VERSION ""

NS_ :

BS_:

BU_: XXX

BO_ 85 EPB: 8 XXX
 SG_ EPB_ActiveFlag : 40|1@1+ (1,0) [0|1] "" XXX
 SG_ CheckSum : 56|8@1+ (1,0) [0|255] "" XXX

BO_ 140 NOTSURE: 8 XXX
 SG_ Heartbeat1 : 15|4@0+ (1,0) [0|15] "" XXX
 SG_ Heartbeat2 : 63|4@0+ (1,0) [0|15] "" XXX

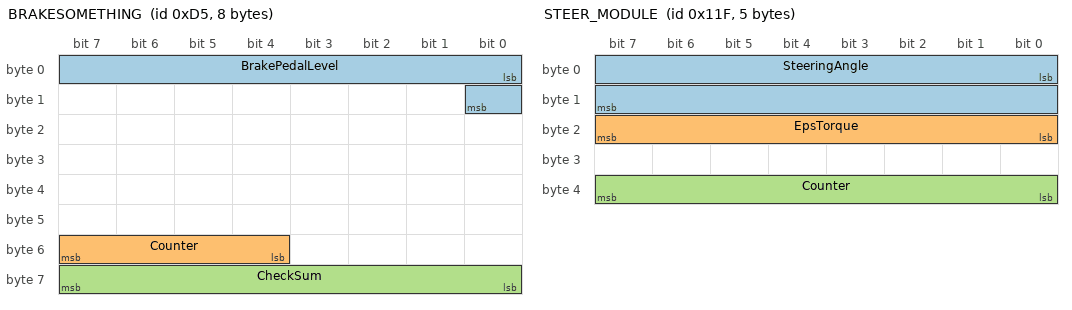
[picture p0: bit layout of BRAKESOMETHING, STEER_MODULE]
BO_ 213 BRAKESOMETHING: 8 XXX
 SG_ BrakePedalLevel : 0|9@1+ (1,0) [0|511] "" XXX
 SG_ Counter : 55|4@0+ (1,0) [0|15] "" XXX
 SG_ CheckSum : 56|8@1+ (1,0) [0|255] "" XXX

BO_ 269 BRAKESOMETHING2: 8 XXX
 SG_ BrakeLevelCoarse : 59|2@0+ (1,0) [0|3] "" XXX

BO_ 287 STEER_MODULE: 5 XXX
 SG_ SteeringAngle : 0|16@1- (0.1,0) [-450|450] "" XXX
 SG_ EpsTorque : 16|8@1+ (1,0) [0|1020] "" XXX
 SG_ Counter : 32|8@1+ (1,0) [0|255] "" XXX

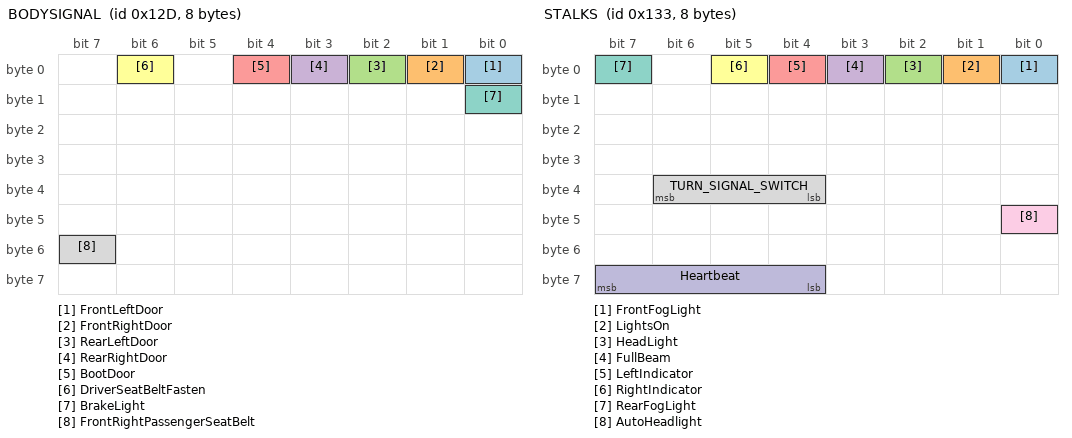
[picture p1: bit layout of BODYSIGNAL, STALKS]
BO_ 301 BODYSIGNAL: 8 XXX
 SG_ FrontLeftDoor : 0|1@0+ (1,0) [0|1] "" XXX
 SG_ FrontRightDoor : 1|1@0+ (1,0) [0|1] "" XXX
 SG_ RearLeftDoor : 2|1@0+ (1,0) [0|1] "" XXX
 SG_ RearRightDoor : 3|1@0+ (1,0) [0|1] "" XXX
 SG_ BootDoor : 4|1@0+ (1,0) [0|1] "" XXX
 SG_ DriverSeatBeltFasten : 6|1@0+ (1,0) [0|1] "" XXX
 SG_ BrakeLight : 8|1@0+ (1,0) [0|1] "" XXX
 SG_ FrontRightPassengerSeatBelt : 55|1@0+ (1,0) [0|1] "" XXX

BO_ 307 STALKS: 8 XXX
 SG_ FrontFogLight : 0|1@0+ (1,0) [0|1] "" XXX
 SG_ LightsOn : 1|1@1+ (1,0) [0|1] "" XXX
 SG_ HeadLight : 2|1@1+ (1,0) [0|1] "" XXX
 SG_ FullBeam : 3|1@1+ (1,0) [0|1] "" XXX
 SG_ LeftIndicator : 4|1@0+ (1,0) [0|1] "" XXX
 SG_ RightIndicator : 5|1@0+ (1,0) [0|1] "" XXX
 SG_ RearFogLight : 7|1@0+ (1,0) [0|1] "" XXX
 SG_ TURN_SIGNAL_SWITCH : 36|3@1+ (1,0) [0|7] "" XXX
 SG_ AutoHeadlight : 40|1@0+ (1,0) [0|1] "" XXX
 SG_ Heartbeat : 63|4@0+ (1,0) [0|15] "" XXX

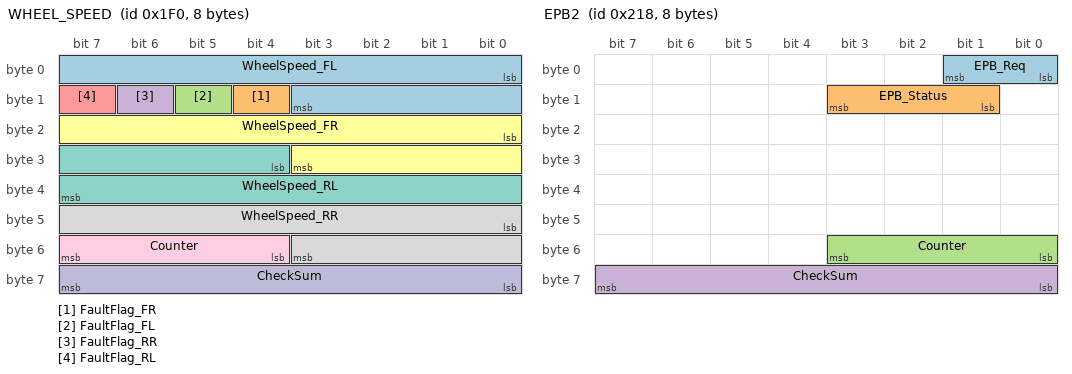
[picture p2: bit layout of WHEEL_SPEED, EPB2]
BO_ 496 WHEEL_SPEED: 8 XXX
 SG_ WheelSpeed_FL : 0|12@1+ (0.06875,0) [0|281.4625] "kph" XXX
 SG_ FaultFlag_FR : 12|1@1+ (1,0) [0|1] "" XXX
 SG_ FaultFlag_FL : 13|1@1+ (1,0) [0|1] "" XXX
 SG_ FaultFlag_RR : 14|1@1+ (1,0) [0|1] "" XXX
 SG_ FaultFlag_RL : 15|1@1+ (1,0) [0|1] "" XXX
 SG_ WheelSpeed_FR : 16|12@1+ (0.06875,0) [0|281.4625] "kph" XXX
 SG_ WheelSpeed_RL : 28|12@1+ (0.06875,0) [0|281.4625] "kph" XXX
 SG_ WheelSpeed_RR : 40|12@1+ (0.06875,0) [0|281.4625] "kph" XXX
 SG_ Counter : 52|4@1+ (1,0) [0|15] "" XXX
 SG_ CheckSum : 56|8@1+ (1,0) [0|255] "" XXX

BO_ 522 ENGINE_RPM: 8 XXX
 SG_ EngineRPM : 31|8@0+ (1,0) [0|255] "" XXX

BO_ 523 ENGINE_GAUGE: 8 XXX
 SG_ EngineRPM : 15|8@0+ (12,0) [0|0] "" XXX

BO_ 536 EPB2: 8 XXX
 SG_ EPB_Req : 0|2@1+ (1,0) [0|3] "" XXX
 SG_ EPB_Status : 9|3@1+ (1,0) [0|7] "" XXX
 SG_ Counter : 48|4@1+ (1,0) [0|15] "" XXX
 SG_ CheckSum : 56|8@1+ (1,0) [0|255] "" XXX

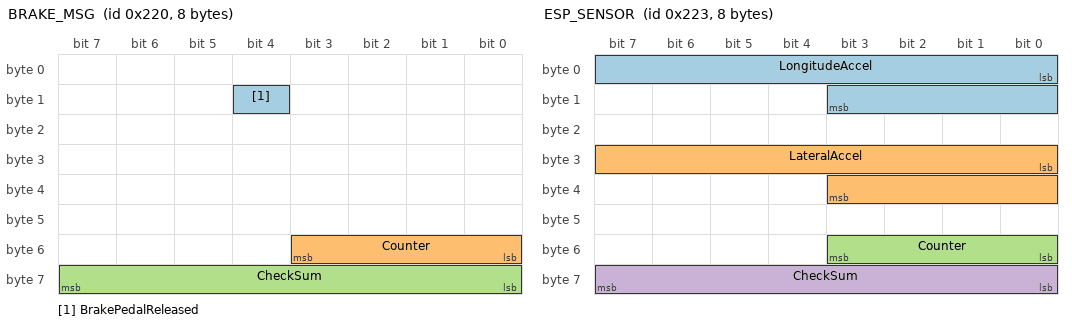
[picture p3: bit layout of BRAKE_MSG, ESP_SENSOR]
BO_ 544 BRAKE_MSG: 8 XXX
 SG_ BrakePedalReleased : 12|1@0+ (1,0) [0|1] "" XXX
 SG_ Counter : 51|4@0+ (1,0) [0|15] "" XXX
 SG_ CheckSum : 56|8@1+ (1,4) [0|255] "" XXX

BO_ 547 ESP_SENSOR: 8 XXX
 SG_ LongitudeAccel : 0|12@1- (0.02,-16) [-2848|1247] "" XXX
 SG_ LateralAccel : 24|12@1- (0.02,-16) [-2848|1247] "" XXX
 SG_ Counter : 51|4@0+ (1,0) [0|15] "" XXX
 SG_ CheckSum : 56|8@1+ (1,0) [0|255] "" XXX

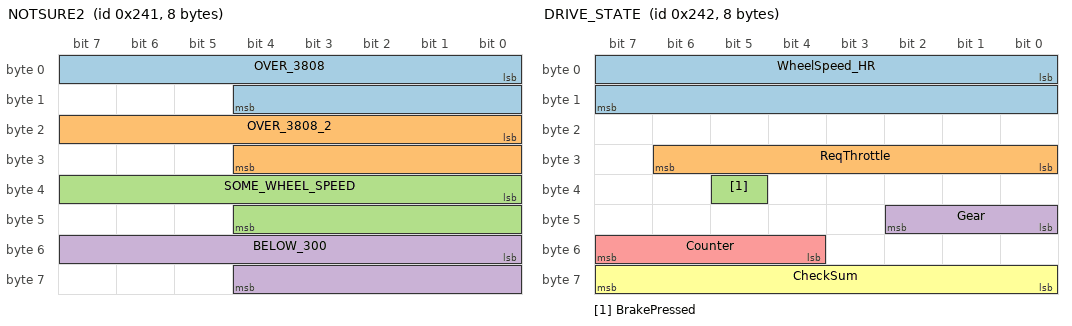
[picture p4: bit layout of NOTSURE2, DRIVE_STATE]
BO_ 577 NOTSURE2: 8 XXX
 SG_ OVER_3808 : 0|13@1+ (1,0) [0|255] "" XXX
 SG_ OVER_3808_2 : 16|13@1+ (1,0) [0|65535] "" XXX
 SG_ SOME_WHEEL_SPEED : 32|13@1- (0.06875,300) [0|15] "" XXX
 SG_ BELOW_300 : 48|13@1+ (0.05,0) [0|255] "" XXX

BO_ 578 DRIVE_STATE: 8 XXX
 SG_ WheelSpeed_HR : 0|16@1+ (0.01706666666,-512) [0|65535] "" XXX
 SG_ ReqThrottle : 30|7@0+ (1,0) [0|127] "" XXX
 SG_ BrakePressed : 37|1@0+ (1,0) [0|1] "" XXX
 SG_ Gear : 40|3@1+ (1,0) [0|7] "" XXX
 SG_ Counter : 55|4@0+ (1,0) [0|15] "" XXX
 SG_ CheckSum : 56|8@1+ (1,0) [0|255] "" XXX

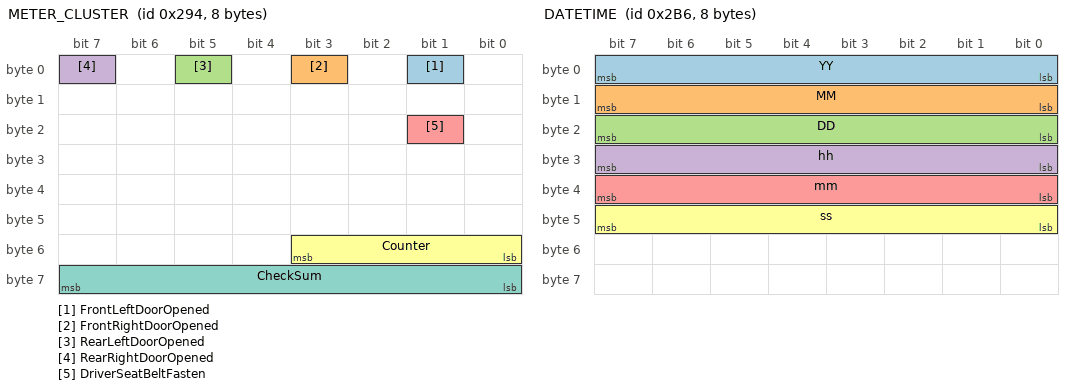
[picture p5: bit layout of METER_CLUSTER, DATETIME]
BO_ 660 METER_CLUSTER: 8 XXX
 SG_ FrontLeftDoorOpened : 1|1@1+ (1,0) [0|511] "" XXX
 SG_ FrontRightDoorOpened : 3|1@0+ (1,0) [0|1] "" XXX
 SG_ RearLeftDoorOpened : 5|1@1+ (1,0) [0|511] "" XXX
 SG_ RearRightDoorOpened : 7|1@0+ (1,0) [0|1] "" XXX
 SG_ DriverSeatBeltFasten : 17|1@0+ (1,0) [0|1] "" XXX
 SG_ Counter : 51|4@0+ (1,0) [0|15] "" XXX
 SG_ CheckSum : 56|8@1+ (1,0) [0|255] "" XXX

BO_ 694 DATETIME: 8 XXX
 SG_ YY : 7|8@0+ (1,0) [0|255] "" XXX
 SG_ MM : 15|8@0+ (1,0) [0|255] "" XXX
 SG_ DD : 23|8@0+ (1,0) [0|255] "" XXX
 SG_ hh : 31|8@0+ (1,0) [0|255] "" XXX
 SG_ mm : 39|8@0+ (1,0) [0|255] "" XXX
 SG_ ss : 47|8@0+ (1,0) [0|255] "" XXX

BO_ 790 MPC_LKAS_CTRL_AND_STATUS: 8 XXX
 SG_ AutoFullBeam_OnOff : 0|2@0+ (1,0) [0|1] "" XXX
 SG_ AutoFullBeamState : 1|1@0+ (1,0) [0|1] "" XXX
 SG_ LeftLaneState : 4|2@1+ (1,0) [0|3] "" XXX
 SG_ LKAS_Config : 6|2@1+ (1,0) [0|3] "" XXX
 SG_ SETME_0x1 : 8|2@1+ (1,0) [0|3] "" XXX
 SG_ ReqHandsOnSteeringWheel : 10|1@1+ (1,0) [0|1] "" XXX
 SG_ MPC_State : 11|4@1+ (1,0) [0|1] "" XXX
 SG_ LKAS_Output : 16|11@1- (1,0) [-1024|1023] "" XXX
 SG_ LKAS_Prepare : 27|1@1+ (1,0) [0|1] "" XXX
 SG_ LKAS_ACTIVE : 28|1@1+ (1,0) [0|3] "" XXX
 SG_ TrafficSignRecognition_OnOff : 30|1@0+ (1,0) [0|1] "" XXX
 SG_ SETME4_0x1 : 32|2@1+ (1,0) [0|3] "" XXX
 SG_ RightLaneState : 34|2@1+ (1,0) [0|3] "" XXX
 SG_ LKAS_OnOff : 36|1@1+ (1,0) [0|3] "" XXX
 SG_ SETME_0x0 : 38|2@1+ (1,0) [0|3] "" XXX
 SG_ TrafficSignRecognition_Result : 40|8@1+ (5,-5) [-5|1270] "" XXX
 SG_ LKAS_AlarmType : 49|2@0+ (1,0) [0|3] "" XXX
 SG_ SETME_0x3 : 51|2@0+ (1,0) [0|3] "" XXX
 SG_ Counter : 52|4@1+ (1,0) [0|15] "" XXX
 SG_ CheckSum : 56|8@1+ (1,0) [0|15] "" XXX

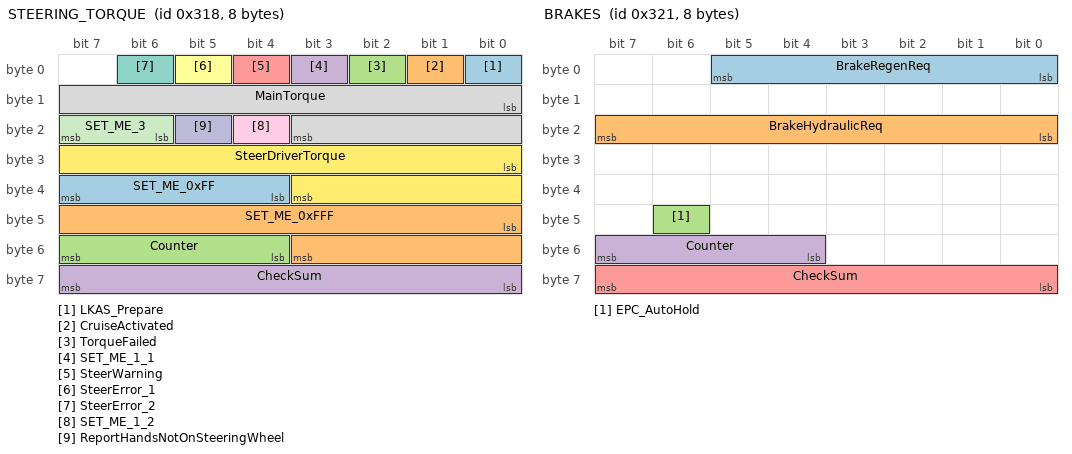
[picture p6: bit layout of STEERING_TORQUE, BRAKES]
BO_ 792 STEERING_TORQUE: 8 XXX
 SG_ LKAS_Prepare : 0|1@1+ (1,0) [0|1] "" XXX
 SG_ CruiseActivated : 1|1@1+ (1,0) [0|1] "" XXX
 SG_ TorqueFailed : 2|1@1+ (1,0) [0|1] "" XXX
 SG_ SET_ME_1_1 : 3|1@1+ (1,0) [0|1] "" XXX
 SG_ SteerWarning : 4|1@1+ (1,0) [0|1] "" XXX
 SG_ SteerError_1 : 5|1@1+ (1,0) [0|1] "" XXX
 SG_ SteerError_2 : 6|1@1+ (1,0) [0|1] "" XXX
 SG_ MainTorque : 8|12@1- (1,0) [-2048|2047] "" XXX
 SG_ SET_ME_1_2 : 20|1@1+ (1,0) [0|1] "" XXX
 SG_ ReportHandsNotOnSteeringWheel : 21|1@1+ (1,0) [0|1] "" XXX
 SG_ SET_ME_3 : 22|2@1+ (1,0) [0|15] "" XXX
 SG_ SteerDriverTorque : 24|12@1- (1,0) [-2048|2047] "" XXX
 SG_ SET_ME_0xFF : 36|4@1+ (1,0) [0|15] "" XXX
 SG_ SET_ME_0xFFF : 40|12@1+ (1,0) [0|4095] "" XXX
 SG_ Counter : 52|4@1+ (1,0) [0|15] "" XXX
 SG_ CheckSum : 56|8@1+ (1,0) [0|255] "" XXX

BO_ 801 BRAKES: 8 XXX
 SG_ BrakeRegenReq : 5|6@0+ (1,0) [0|63] "" XXX
 SG_ BrakeHydraulicReq : 23|8@0+ (1,0) [0|255] "" XXX
 SG_ EPC_AutoHold : 46|1@0+ (1,0) [0|1] "" XXX
 SG_ Counter : 55|4@0+ (1,0) [0|15] "" XXX
 SG_ CheckSum : 63|8@0+ (1,0) [0|255] "" XXX

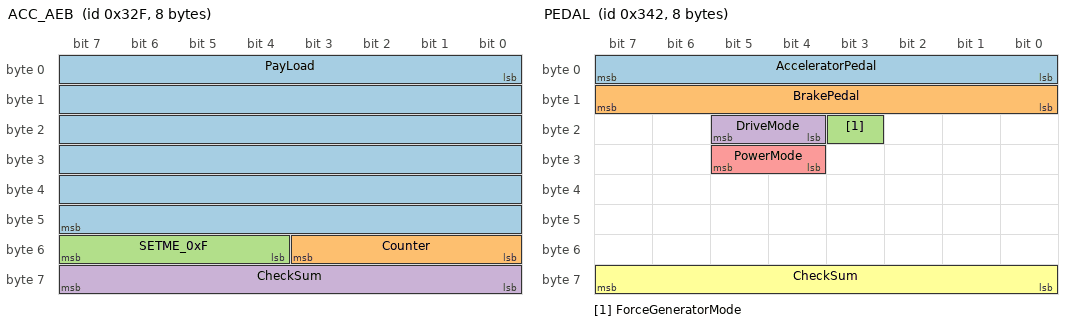
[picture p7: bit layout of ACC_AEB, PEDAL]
BO_ 815 ACC_AEB: 8 XXX
 SG_ PayLoad : 0|48@1+ (1,0) [0|4.5035996273705e+15] "" XXX
 SG_ Counter : 48|4@1+ (1,0) [0|15] "" XXX
 SG_ SETME_0xF : 55|4@0+ (1,0) [0|15] "" XXX
 SG_ CheckSum : 56|8@1+ (1,0) [0|255] "" XXX

BO_ 834 PEDAL: 8 XXX
 SG_ AcceleratorPedal : 0|8@1+ (0.01,0) [0|2.55] "" XXX
 SG_ BrakePedal : 8|8@1+ (0.01,0) [0|2.55] "" XXX
 SG_ ForceGeneratorMode : 19|1@1+ (1,0) [0|1] "" XXX
 SG_ DriveMode : 20|2@1+ (1,0) [0|255] "" XXX
 SG_ PowerMode : 28|2@1+ (1,0) [0|1] "" XXX
 SG_ CheckSum : 56|8@1+ (1,0) [0|255] "" XXX

BO_ 848 RADAR_NOTSURE: 8 XXX

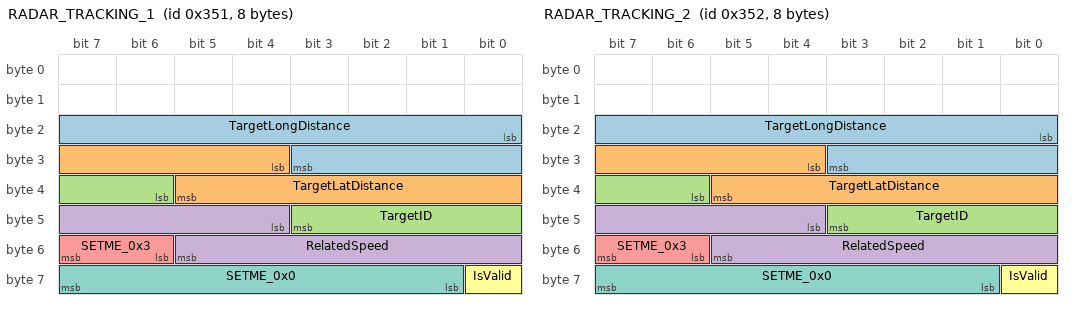
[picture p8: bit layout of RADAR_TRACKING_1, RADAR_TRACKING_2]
BO_ 849 RADAR_TRACKING_1: 8 XXX
 SG_ TargetLongDistance : 16|12@1- (0.0625,-4.5) [-61.44|61.41] "m" XXX
 SG_ TargetLatDistance : 28|10@1+ (0.0625,-32) [-15.36|15.33] "m" XXX
 SG_ TargetID : 38|6@1+ (1,0) [0|63] "" XXX
 SG_ RelatedSpeed : 44|10@1+ (1,-512) [-512|511] "km/s" XXX
 SG_ SETME_0x3 : 54|2@1+ (1,0) [0|3] "" XXX
 SG_ IsValid : 56|1@0+ (1,0) [0|1] "" XXX
 SG_ SETME_0x0 : 57|7@1+ (1,0) [0|127] "" XXX

BO_ 850 RADAR_TRACKING_2: 8 XXX
 SG_ TargetLongDistance : 16|12@1- (0.0625,-4.5) [-61.44|61.41] "m" XXX
 SG_ TargetLatDistance : 28|10@1+ (0.0625,-32) [-15.36|15.33] "m" XXX
 SG_ TargetID : 38|6@1+ (1,0) [0|63] "" XXX
 SG_ RelatedSpeed : 44|10@1+ (1,-512) [-512|511] "km/s" XXX
 SG_ SETME_0x3 : 54|2@1+ (1,0) [0|3] "" XXX
 SG_ IsValid : 56|1@0+ (1,0) [0|1] "" XXX
 SG_ SETME_0x0 : 57|7@1+ (1,0) [0|127] "" XXX

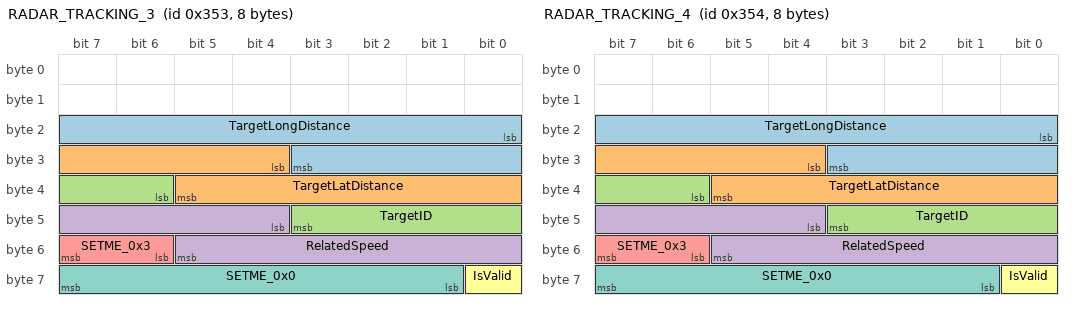
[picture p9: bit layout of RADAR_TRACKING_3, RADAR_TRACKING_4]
BO_ 851 RADAR_TRACKING_3: 8 XXX
 SG_ TargetLongDistance : 16|12@1- (0.0625,-4.5) [-61.44|61.41] "m" XXX
 SG_ TargetLatDistance : 28|10@1+ (0.0625,-32) [-15.36|15.33] "m" XXX
 SG_ TargetID : 38|6@1+ (1,0) [0|63] "" XXX
 SG_ RelatedSpeed : 44|10@1+ (1,-512) [-512|511] "km/s" XXX
 SG_ SETME_0x3 : 54|2@1+ (1,0) [0|3] "" XXX
 SG_ IsValid : 56|1@0+ (1,0) [0|1] "" XXX
 SG_ SETME_0x0 : 57|7@1+ (1,0) [0|127] "" XXX

BO_ 852 RADAR_TRACKING_4: 8 XXX
 SG_ TargetLongDistance : 16|12@1- (0.0625,-4.5) [-61.44|61.41] "m" XXX
 SG_ TargetLatDistance : 28|10@1+ (0.0625,-32) [-15.36|15.33] "m" XXX
 SG_ TargetID : 38|6@1+ (1,0) [0|63] "" XXX
 SG_ RelatedSpeed : 44|10@1+ (1,-512) [-512|511] "km/s" XXX
 SG_ SETME_0x3 : 54|2@1+ (1,0) [0|3] "" XXX
 SG_ IsValid : 56|1@0+ (1,0) [0|1] "" XXX
 SG_ SETME_0x0 : 57|7@1+ (1,0) [0|127] "" XXX

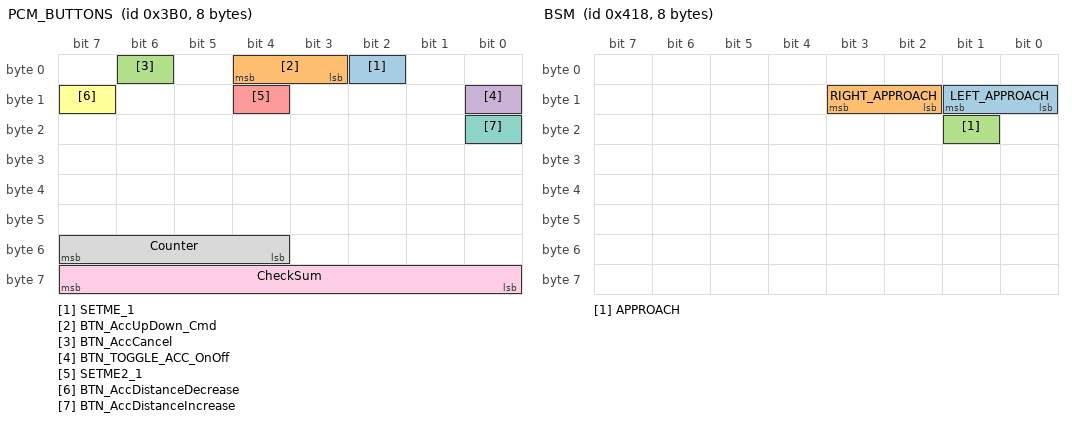
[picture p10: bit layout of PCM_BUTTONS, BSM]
BO_ 944 PCM_BUTTONS: 8 XXX
 SG_ SETME_1 : 2|1@0+ (1,0) [0|1] "" XXX
 SG_ BTN_AccUpDown_Cmd : 4|2@0+ (1,0) [0|3] "" XXX
 SG_ BTN_AccCancel : 6|1@0+ (1,0) [0|1] "" XXX
 SG_ BTN_TOGGLE_ACC_OnOff : 8|1@0+ (1,0) [0|1] "" XXX
 SG_ SETME2_1 : 12|1@0+ (1,0) [0|1] "" XXX
 SG_ BTN_AccDistanceDecrease : 15|1@0+ (1,0) [0|1] "" XXX
 SG_ BTN_AccDistanceIncrease : 16|1@0+ (1,0) [0|1] "" XXX
 SG_ Counter : 52|4@1+ (1,0) [0|15] "" XXX
 SG_ CheckSum : 56|8@1+ (1,0) [0|255] "" XXX

BO_ 1048 BSM: 8 XXX
 SG_ LEFT_APPROACH : 9|2@0+ (1,0) [0|1] "" XXX
 SG_ RIGHT_APPROACH : 11|2@0+ (1,0) [0|1] "" XXX
 SG_ APPROACH : 17|1@0+ (1,0) [0|1] "" XXX

BO_ 1172 NEW_MSG_494: 8 XXX
 SG_ BrakePedalReleased : 47|1@0+ (1,0) [0|1] "" XXX
 SG_ CheckSum : 56|8@1+ (1,0) [0|255] "" XXX

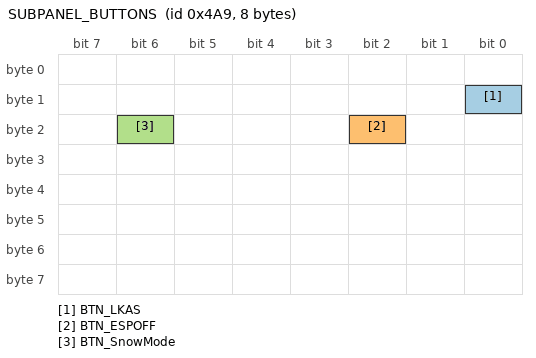
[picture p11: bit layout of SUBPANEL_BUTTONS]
BO_ 1193 SUBPANEL_BUTTONS: 8 XXX
 SG_ BTN_LKAS : 8|1@0+ (1,0) [0|1] "" XXX
 SG_ BTN_ESPOFF : 18|1@0+ (1,0) [0|1] "" XXX
 SG_ BTN_SnowMode : 22|1@0+ (1,0) [0|1] "" XXX

VAL_ 269 BrakeLevelCoarse 0 "RELEASED" 2 "VERYLIGHT" 1 "BRAKING";
VAL_ 307 TURN_SIGNAL_SWITCH 0 "Invalid" 1 "OFFGear" 2 "LeftSteeringShortLift" 3 "LeftSteeringLongLift" 4 "RightSteeringShortLift" 5 "RightSteeringLongLift" 7 "Unavaliable";
VAL_ 536 EPB_Req 0 "IDLE" 1 "RELEASE" 2 "ENGAGED" 3 "NOTSURE";
VAL_ 536 EPB_Status 0 "RELEASING" 1 "RELEASED" 2 "ENGAGING" 3 "ENGAGED" 4 "INHIBITED_ERROR";
VAL_ 578 Gear 4 "D" 2 "R" 3 "N" 1 "P";
VAL_ 834 DriveMode 2 "SPORT" 1 "ECO" 0 "SNOW";
VAL_ 834 PowerMode 3 "HEV" 2 "FORCE_EV" 1 "EV";
VAL_ 944 BTN_AccUpDown_Cmd 0 "NOTPRESSED" 1 "DOWN_SETSPEED" 3 "UP_RESETSPEED";
